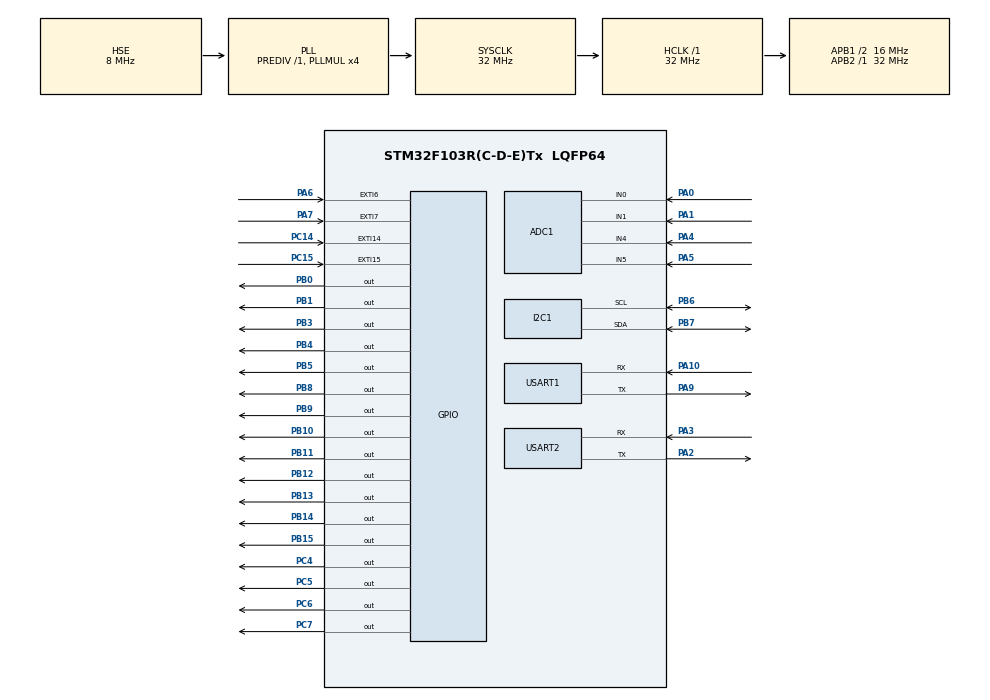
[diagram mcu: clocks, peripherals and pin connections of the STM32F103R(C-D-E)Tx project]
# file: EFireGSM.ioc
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Mcu.Family=STM32F1
Dma.USART2_RX.2.PeriphDataAlignment=DMA_PDATAALIGN_BYTE
NVIC.ADC1_2_IRQn=true\:5\:0\:false\:false\:true\:true\:true
Dma.ADC1.1.MemDataAlignment=DMA_MDATAALIGN_HALFWORD
NVIC.DMA1_Channel5_IRQn=true\:5\:0\:false\:true\:true\:3\:true\:false
PB10.GPIO_Speed=GPIO_SPEED_FREQ_HIGH
PB10.GPIO_PuPd=GPIO_PULLUP
ADC1.ContinuousConvMode=ENABLE
ADC1.Channel-17\#ChannelRegularConversion=ADC_CHANNEL_5
ADC1.Rank-17\#ChannelRegularConversion=4
PB9.GPIO_ModeDefaultOutputPP=GPIO_MODE_OUTPUT_PP
NVIC.TIM1_UP_IRQn=true\:0\:0\:false\:false\:true\:false\:false
PB11.GPIO_PuPd=GPIO_PULLUP
PB11.Signal=GPIO_Output
PB13.Signal=GPIO_Output
PB15.Signal=GPIO_Output
RCC.SYSCLKSource=RCC_SYSCLKSOURCE_PLLCLK
ProjectManager.StackSize=0x400
PD1-OSC_OUT.Signal=RCC_OSC_OUT
ADC1.Channel-5\#ChannelRegularConversion=ADC_CHANNEL_0
Dma.ADC1.1.Instance=DMA1_Channel1
PB1.GPIO_PuPd=GPIO_PULLUP
RCC.HCLKFreq_Value=32000000
RCC.APB2TimFreq_Value=32000000
PB6.Signal=I2C1_SCL
PC7.Signal=GPIO_Output
ADC1.InjNumberOfConversion=0
Dma.ADC1.1.PeriphDataAlignment=DMA_PDATAALIGN_HALFWORD
PB6.Mode=I2C
Dma.USART2_RX.2.Priority=DMA_PRIORITY_HIGH
Dma.USART2_RX.2.MemDataAlignment=DMA_MDATAALIGN_BYTE
RCC.AHBFreq_Value=32000000
Dma.USART1_RX.0.Priority=DMA_PRIORITY_HIGH
NVIC.EXTI15_10_IRQn=true\:6\:0\:true\:false\:true\:true\:true
FREERTOS.configUSE_TIMERS=1
RCC.PLLMUL=RCC_PLL_MUL4
VP_ADC1_Vref_Input.Mode=IN-Vrefint
PC15-OSC32_OUT.GPIO_ModeDefaultEXTI=GPIO_MODE_IT_RISING_FALLING
PA6.GPIO_PuPd=GPIO_PULLUP
PB3.GPIO_PuPd=GPIO_PULLUP
PA14.Mode=Serial_Wire
VP_SYS_VS_tim1.Mode=TIM1
Dma.ADC1.1.Priority=DMA_PRIORITY_LOW
PB7.Signal=I2C1_SDA
Dma.ADC1.1.Mode=DMA_CIRCULAR
SH.ADCx_IN0.0=ADC1_IN0,IN0
TIM6.Period=1000
VP_FREERTOS_VS_CMSIS_V1.Mode=CMSIS_V1
Dma.USART1_RX.0.MemInc=DMA_MINC_ENABLE
FREERTOS.configTOTAL_HEAP_SIZE=25600
Mcu.Package=LQFP64
PB9.Signal=GPIO_Output
PB14.GPIO_PuPd=GPIO_PULLUP
PB1.Signal=GPIO_Output
PA6.Signal=GPXTI6
NVIC.TimeBase=TIM1_UP_IRQn
PB15.GPIO_PuPd=GPIO_PULLUP
USART2.VirtualMode=VM_ASYNC
Dma.ADC1.1.Direction=DMA_PERIPH_TO_MEMORY
ADC1.SamplingTime-13\#ChannelRegularConversion=ADC_SAMPLETIME_239CYCLES_5
Dma.ADC1.1.MemInc=DMA_MINC_ENABLE
NVIC.TimeBaseIP=TIM1
PA10.Signal=USART1_RX
PB9.GPIO_PuPd=GPIO_PULLUP
PC6.GPIO_PuPd=GPIO_PULLUP
Dma.USART2_RX.2.Direction=DMA_PERIPH_TO_MEMORY
ADC1.SamplingTime-17\#ChannelRegularConversion=ADC_SAMPLETIME_239CYCLES_5
SH.ADCx_IN1.0=ADC1_IN1,IN1
PB9.GPIO_Speed=GPIO_SPEED_FREQ_HIGH
Dma.Request2=USART2_RX
Dma.Request1=ADC1
RCC.APB1TimFreq_Value=32000000
Dma.USART1_RX.0.Mode=DMA_NORMAL
PC5.Signal=GPIO_Output
NVIC.USART1_IRQn=true\:5\:0\:false\:true\:true\:2\:true\:true
Dma.Request0=USART1_RX
Dma.USART1_RX.0.Instance=DMA1_Channel5
PB4.Signal=GPIO_Output
PA3.Signal=USART2_RX
RCC.PLLSourceVirtual=RCC_PLLSOURCE_HSE
FREERTOS.configTIMER_QUEUE_LENGTH=10
NVIC.DMA1_Channel6_IRQn=true\:5\:0\:true\:true\:true\:4\:true\:false
PA6.GPIO_ModeDefaultEXTI=GPIO_MODE_IT_RISING_FALLING
FREERTOS.Tasks01=defaultTask,0,256,StartDefaultTask,Default,NULL,Dynamic,NULL,NULL
PD1-OSC_OUT.Mode=HSE-External-Oscillator
Dma.USART1_RX.0.PeriphDataAlignment=DMA_PDATAALIGN_BYTE
PA10.Mode=Asynchronous
ADC1.SamplingTime-16\#ChannelRegularConversion=ADC_SAMPLETIME_239CYCLES_5
PC4.GPIO_PuPd=GPIO_PULLUP
ADC1.Rank-18\#ChannelRegularConversion=5
PA7.GPIO_ModeDefaultEXTI=GPIO_MODE_IT_RISING_FALLING
PB8.GPIO_PuPd=GPIO_PULLUP
TIM6.Prescaler=3200
PC4.Signal=GPIO_Output
PC6.Signal=GPIO_Output
VP_TIM6_VS_ClockSourceINT.Mode=Enable_Timer
ADC1.DiscontinuousConvMode=DISABLE
PD0-OSC_IN.Signal=RCC_OSC_IN
ADC1.Channel-13\#ChannelRegularConversion=ADC_CHANNEL_1
RCC.APB1CLKDivider=RCC_HCLK_DIV2
PC14-OSC32_IN.Signal=GPXTI14
PC5.GPIO_PuPd=GPIO_PULLUP
NVIC.USART2_IRQn=true\:6\:0\:true\:true\:true\:1\:true\:true
Dma.USART2_RX.2.Mode=DMA_NORMAL
PA0-WKUP.Signal=ADCx_IN0
NVIC.TIM6_IRQn=true\:5\:0\:true\:false\:true\:true\:true
RCC.ADCPresc=RCC_ADCPCLK2_DIV4
PA3.Mode=Asynchronous
PA13.Signal=SYS_JTMS-SWDIO
TIM6.AutoReloadPreload=TIM_AUTORELOAD_PRELOAD_ENABLE
ADC1.Rank-13\#ChannelRegularConversion=2
PA9.Mode=Asynchronous
Dma.USART2_RX.2.MemInc=DMA_MINC_ENABLE
ProjectManager.TargetToolchain=EWARM V8
FREERTOS.configTIMER_TASK_STACK_DEPTH=0x100
ADC1.Channel-18\#ChannelRegularConversion=ADC_CHANNEL_VREFINT
Dma.USART1_RX.0.Direction=DMA_PERIPH_TO_MEMORY
PA9.Signal=USART1_TX
PB4.GPIO_PuPd=GPIO_PULLUP
RCC.USBFreq_Value=32000000
PC7.GPIO_PuPd=GPIO_PULLUP
PC15-OSC32_OUT.Signal=GPXTI15
PA1.Signal=ADCx_IN1
PA7.GPIO_PuPd=GPIO_PULLUP
Dma.USART1_RX.0.PeriphInc=DMA_PINC_DISABLE
PD0-OSC_IN.Mode=HSE-External-Oscillator
PB10.Signal=GPIO_Output
PB14.Signal=GPIO_Output
PA5.Signal=ADCx_IN5
board=custom
PC14-OSC32_IN.GPIO_ModeDefaultEXTI=GPIO_MODE_IT_RISING_FALLING
PB13.GPIO_PuPd=GPIO_PULLUP
Dma.USART2_RX.2.PeriphInc=DMA_PINC_DISABLE
RCC.APB2Freq_Value=32000000
Dma.USART1_RX.0.MemDataAlignment=DMA_MDATAALIGN_BYTE
SH.ADCx_IN4.0=ADC1_IN4,IN4
PC15-OSC32_OUT.GPIO_PuPd=GPIO_PULLUP
ADC1.Channel-16\#ChannelRegularConversion=ADC_CHANNEL_4
Dma.ADC1.1.PeriphInc=DMA_PINC_DISABLE
ADC1.NbrOfConversion=5
PA13.Mode=Serial_Wire
Mcu.Name=STM32F103R(C-D-E)Tx
PA2.Signal=USART2_TX
PB3.Signal=GPIO_Output
PA4.Signal=ADCx_IN4
RCC.SYSCLKFreq_VALUE=32000000
ADC1.Rank-16\#ChannelRegularConversion=3
PB5.Signal=GPIO_Output
ADC1.master=1
Dma.USART2_RX.2.Instance=DMA1_Channel6
PB5.GPIO_PuPd=GPIO_PULLUP
USART1.VirtualMode=VM_ASYNC
PB7.Mode=I2C
NVIC.EXTI9_5_IRQn=true\:5\:0\:true\:false\:true\:true\:true
PA14.Signal=SYS_JTCK-SWCLK
ProjectManager.HeapSize=0x200
ADC1.SamplingTime-5\#ChannelRegularConversion=ADC_SAMPLETIME_239CYCLES_5
SH.ADCx_IN5.0=ADC1_IN5,IN5
NVIC.PriorityGroup=NVIC_PRIORITYGROUP_4
ADC1.NbrOfConversionFlag=1
PA2.Mode=Asynchronous
PB8.Signal=GPIO_Output
PC14-OSC32_IN.GPIO_PuPd=GPIO_PULLUP
NVIC.DMA1_Channel1_IRQn=true\:5\:0\:false\:true\:true\:5\:true\:false
PB12.GPIO_PuPd=GPIO_PULLUP
RCC.APB1Freq_Value=16000000
PB8.GPIO_Speed=GPIO_SPEED_FREQ_HIGH
PB0.Signal=GPIO_Output
ADC1.SamplingTime-18\#ChannelRegularConversion=ADC_SAMPLETIME_239CYCLES_5
ADC1.Rank-5\#ChannelRegularConversion=1
PB12.Signal=GPIO_Output
PB0.GPIO_PuPd=GPIO_PULLUP
PA7.Signal=GPXTI7

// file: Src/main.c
/* USER CODE BEGIN Header */
/**
  ******************************************************************************
  * @file           : main.c
  * @brief          : Main program body
  ******************************************************************************
  * @attention
  *
  * <h2><center>&copy; Copyright (c) 2020 STMicroelectronics.
  * All rights reserved.</center></h2>
  *
  * This software component is licensed by ST under Ultimate Liberty license
  * SLA0044, the "License"; You may not use this file except in compliance with
  * the License. You may obtain a copy of the License at:
  *                             www.st.com/SLA0044
  *
  ******************************************************************************
  */
/* USER CODE END Header */
#include "main.h"
#include "cmsis_os.h"
#include "adc.h"
#include "dma.h"
#include "i2c.h"
#include "tim.h"
#include "usart.h"
#include "gpio.h"

/* USER CODE BEGIN Includes */
#include "stdio.h"
/* USER CODE END Includes */

void SystemClock_Config(void);
void MX_FREERTOS_Init(void);
static void MX_NVIC_Init(void);

/* USER CODE BEGIN 0 */
int fputc(int ch,FILE *f)
{
  HAL_UART_Transmit(&huart1,(uint8_t*)&ch,1,1000);
  return ch;
}
/* USER CODE END 0 */

int main(void)
{

  /* MCU Configuration--------------------------------------------------------*/

  /* Reset of all peripherals, Initializes the Flash interface and the Systick. */
  HAL_Init();

  /* Configure the system clock */
  SystemClock_Config();

  /* Initialize all configured peripherals */
  MX_GPIO_Init();
  MX_DMA_Init();
  MX_I2C1_Init();
  MX_USART1_UART_Init();
  MX_USART2_UART_Init();
  MX_ADC1_Init();
  MX_TIM6_Init();

  /* Initialize interrupts */
  MX_NVIC_Init();

  /* Call init function for freertos objects (in freertos.c) */
  MX_FREERTOS_Init();
  /* Start scheduler */
  osKernelStart();

  /* We should never get here as control is now taken by the scheduler */
  /* Infinite loop */
  while (1)
  {

  }
}

void SystemClock_Config(void)
{
  RCC_OscInitTypeDef RCC_OscInitStruct = {0};
  RCC_ClkInitTypeDef RCC_ClkInitStruct = {0};
  RCC_PeriphCLKInitTypeDef PeriphClkInit = {0};

  /** Initializes the RCC Oscillators according to the specified parameters
  * in the RCC_OscInitTypeDef structure.
  */
  RCC_OscInitStruct.OscillatorType = RCC_OSCILLATORTYPE_HSE;
  RCC_OscInitStruct.HSEState = RCC_HSE_ON;
  RCC_OscInitStruct.HSEPredivValue = RCC_HSE_PREDIV_DIV1;
  RCC_OscInitStruct.HSIState = RCC_HSI_ON;
  RCC_OscInitStruct.PLL.PLLState = RCC_PLL_ON;
  RCC_OscInitStruct.PLL.PLLSource = RCC_PLLSOURCE_HSE;
  RCC_OscInitStruct.PLL.PLLMUL = RCC_PLL_MUL4;
  if (HAL_RCC_OscConfig(&RCC_OscInitStruct) != HAL_OK)
  {
    Error_Handler();
  }
  /** Initializes the CPU, AHB and APB buses clocks
  */
  RCC_ClkInitStruct.ClockType = RCC_CLOCKTYPE_HCLK|RCC_CLOCKTYPE_SYSCLK
                              |RCC_CLOCKTYPE_PCLK1|RCC_CLOCKTYPE_PCLK2;
  RCC_ClkInitStruct.SYSCLKSource = RCC_SYSCLKSOURCE_PLLCLK;
  RCC_ClkInitStruct.AHBCLKDivider = RCC_SYSCLK_DIV1;
  RCC_ClkInitStruct.APB1CLKDivider = RCC_HCLK_DIV2;
  RCC_ClkInitStruct.APB2CLKDivider = RCC_HCLK_DIV1;

  if (HAL_RCC_ClockConfig(&RCC_ClkInitStruct, FLASH_LATENCY_1) != HAL_OK)
  {
    Error_Handler();
  }
  PeriphClkInit.PeriphClockSelection = RCC_PERIPHCLK_ADC;
  PeriphClkInit.AdcClockSelection = RCC_ADCPCLK2_DIV4;
  if (HAL_RCCEx_PeriphCLKConfig(&PeriphClkInit) != HAL_OK)
  {
    Error_Handler();
  }
}

/**
  * @brief NVIC Configuration.
  * @retval None
  */
static void MX_NVIC_Init(void)
{
  /* USART2_IRQn interrupt configuration */
  HAL_NVIC_SetPriority(USART2_IRQn, 6, 0);
  HAL_NVIC_EnableIRQ(USART2_IRQn);
  /* USART1_IRQn interrupt configuration */
  HAL_NVIC_SetPriority(USART1_IRQn, 5, 0);
  HAL_NVIC_EnableIRQ(USART1_IRQn);
  /* DMA1_Channel5_IRQn interrupt configuration */
  HAL_NVIC_SetPriority(DMA1_Channel5_IRQn, 5, 0);
  HAL_NVIC_EnableIRQ(DMA1_Channel5_IRQn);
  /* DMA1_Channel6_IRQn interrupt configuration */
  HAL_NVIC_SetPriority(DMA1_Channel6_IRQn, 5, 0);
  HAL_NVIC_EnableIRQ(DMA1_Channel6_IRQn);
  /* DMA1_Channel1_IRQn interrupt configuration */
  HAL_NVIC_SetPriority(DMA1_Channel1_IRQn, 5, 0);
  HAL_NVIC_EnableIRQ(DMA1_Channel1_IRQn);
}

void HAL_TIM_PeriodElapsedCallback(TIM_HandleTypeDef *htim)
{
  if (htim->Instance == TIM1) {
    HAL_IncTick();
  }
}

void Error_Handler(void)
{
}

/************************ (C) COPYRIGHT STMicroelectronics *****END OF FILE****/

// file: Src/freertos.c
/* USER CODE BEGIN Header */
/**
  ******************************************************************************
  * File Name          : freertos.c
  * Description        : Code for freertos applications
  ******************************************************************************
  * @attention
  *
  * <h2><center>&copy; Copyright (c) 2020 STMicroelectronics.
  * All rights reserved.</center></h2>
  *
  * This software component is licensed by ST under Ultimate Liberty license
  * SLA0044, the "License"; You may not use this file except in compliance with
  * the License. You may obtain a copy of the License at:
  *                             www.st.com/SLA0044
  *
  ******************************************************************************
  */
/* USER CODE END Header */

#include "FreeRTOS.h"
#include "task.h"
#include "main.h"
#include "cmsis_os.h"

//osThreadId defaultTaskHandle;

//void StartDefaultTask(void const * argument);

void MX_FREERTOS_Init(void); /* (MISRA C 2004 rule 8.1) */

/* GetIdleTaskMemory prototype (linked to static allocation support) */
void vApplicationGetIdleTaskMemory( StaticTask_t **ppxIdleTaskTCBBuffer, StackType_t **ppxIdleTaskStackBuffer, uint32_t *pulIdleTaskStackSize );

/* GetTimerTaskMemory prototype (linked to static allocation support) */
void vApplicationGetTimerTaskMemory( StaticTask_t **ppxTimerTaskTCBBuffer, StackType_t **ppxTimerTaskStackBuffer, uint32_t *pulTimerTaskStackSize );

/* USER CODE BEGIN GET_IDLE_TASK_MEMORY */
static StaticTask_t xIdleTaskTCBBuffer;
static StackType_t xIdleStack[configMINIMAL_STACK_SIZE];

void vApplicationGetIdleTaskMemory( StaticTask_t **ppxIdleTaskTCBBuffer, StackType_t **ppxIdleTaskStackBuffer, uint32_t *pulIdleTaskStackSize )
{
  *ppxIdleTaskTCBBuffer = &xIdleTaskTCBBuffer;
  *ppxIdleTaskStackBuffer = &xIdleStack[0];
  *pulIdleTaskStackSize = configMINIMAL_STACK_SIZE;
  /* place for user code */
}
/* USER CODE END GET_IDLE_TASK_MEMORY */

/* USER CODE BEGIN GET_TIMER_TASK_MEMORY */
static StaticTask_t xTimerTaskTCBBuffer;
static StackType_t xTimerStack[configTIMER_TASK_STACK_DEPTH];

void vApplicationGetTimerTaskMemory( StaticTask_t **ppxTimerTaskTCBBuffer, StackType_t **ppxTimerTaskStackBuffer, uint32_t *pulTimerTaskStackSize )
{
  *ppxTimerTaskTCBBuffer = &xTimerTaskTCBBuffer;
  *ppxTimerTaskStackBuffer = &xTimerStack[0];
  *pulTimerTaskStackSize = configTIMER_TASK_STACK_DEPTH;
  /* place for user code */
}
/* USER CODE END GET_TIMER_TASK_MEMORY */

void MX_FREERTOS_Init(void) {

  /* Create the thread(s) */
  /* definition and creation of defaultTask */
//  osThreadDef(defaultTask, StartDefaultTask, osPriorityNormal, 0, 256);
//  defaultTaskHandle = osThreadCreate(osThread(defaultTask), NULL);

  /* USER CODE BEGIN RTOS_THREADS */
  /* add threads, ... */

  WinThread_Init();
  /* USER CODE END RTOS_THREADS */

}

void StartDefaultTask(void const * argument)
{
  for(;;)
  {
    osDelay(1);
  }
}

/************************ (C) COPYRIGHT STMicroelectronics *****END OF FILE****/
